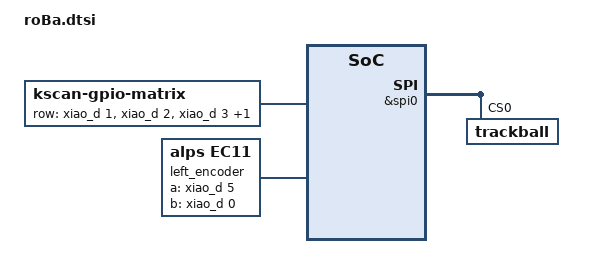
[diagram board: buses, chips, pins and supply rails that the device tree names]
#include <dt-bindings/zmk/matrix_transform.h>
#include <physical_layouts.dtsi>
#include <input/processors.dtsi>    /* ← 追加：input processors を読み込む */

 / {
    chosen {
        zmk,physical-layout = &roba_physical_layout;
    };

    roba_physical_layout: roba_physical_layout {
        compatible = "zmk,physical-layout";
        display-name = "Default";
        transform = <&default_transform>;
        kscan = <&kscan0>;

        keys  /* ... （あなたの既存 keys 配列をそのまま） ... */ ;
    };

    default_transform: keymap_transform_0 {
        compatible = "zmk,matrix-transform";
        columns = <11>;
        rows = <4>;
        map = < /* ... 既存 map ... */ >;
    };

    kscan0: kscan {
        compatible = "zmk,kscan-gpio-matrix";
        label = "KSCAN";
        diode-direction = "col2row";
        row-gpios =
            <&xiao_d 1 (GPIO_ACTIVE_HIGH | GPIO_PULL_DOWN)>,
            <&xiao_d 2 (GPIO_ACTIVE_HIGH | GPIO_PULL_DOWN)>,
            <&xiao_d 3 (GPIO_ACTIVE_HIGH | GPIO_PULL_DOWN)>,
            <&xiao_d 6 (GPIO_ACTIVE_HIGH | GPIO_PULL_DOWN)>;
    };

    left_encoder: encoder_left {
        compatible = "alps,ec11";
        a-gpios = <&xiao_d 5 (GPIO_ACTIVE_HIGH | GPIO_PULL_UP)>;
        b-gpios = <&xiao_d 0 (GPIO_ACTIVE_HIGH | GPIO_PULL_UP)>;
        steps = <12>;
        status = "okay";
    };

    right_encoder: encoder_right {
        status = "disabled";
    };

    /* --- ここを置き換え： sensors ノードはエンコーダ用にそのまま残す --- */
    sensors: sensors {
        compatible = "zmk,keymap-sensors";
        sensors = <&left_encoder &right_encoder>;
        /* 全体の既定トリガー数（必要なら調整） */
        triggers-per-rotation = <48>;
    };

    /* --- trackball ノードを有効化（SPI経由のトラックボールがある場合） --- */
    &spi0 {
        status = "okay";

        trackball: trackball@0 {
            status = "okay";
            reg = <0>;
            /* デフォルト CPI (conf での指定が優先する場合あり) */
            /* ここではノードを有効にしておくだけでOK */
        };
    };

    /* --- トラックボール入力リスナー（必ず enabled に） --- */
    trackball_listener: trackball_listener {
        compatible = "zmk,input-listener";
        status = "okay";

        /*
         * Base input processors (通常時)
         *  - ここではデフォルト（倍率 1:1、スクロールそのまま）にしておきます。
         *  - 必要なら base でもスケーリングを入れてください。
         */
        input-processors = < 
            /* X/Y scaler multiplier=1 divisor=1 (no change) */
            &zip_xy_scaler 1 1
            /* scroll scaler default (no change) */
            &zip_scroll_scaler 1 1
        >;

        /*
         * レイヤー別オーバーライド
         *  - ここで layers=<8> にマッチする override を追加。
         *  - layer 8 = MOUSE レイヤー（あなたの keymap 配列で確認済み）
         *
         *  この override が有効なとき、X/Y とスクロールを 1/2 にします（遅くする）。
         */
        mouse_slow_override {
            layers = <8>; /* MOUSE レイヤー番号 */
            input-processors = <
                /* X/Y を 1/2 にする（multiplier=1, divisor=2）*/
                &zip_xy_scaler 1 2
                /* スクロールも 1/2 にする */
                &zip_scroll_scaler 1 2
            >;
        };

        /*
         * もしスクロールレイヤー（scroll-layers）も別扱いにしたければ、
         * そこ用の override を追加できます（例：layers = <5>;）。
         */
    };
 }; /* end / */
